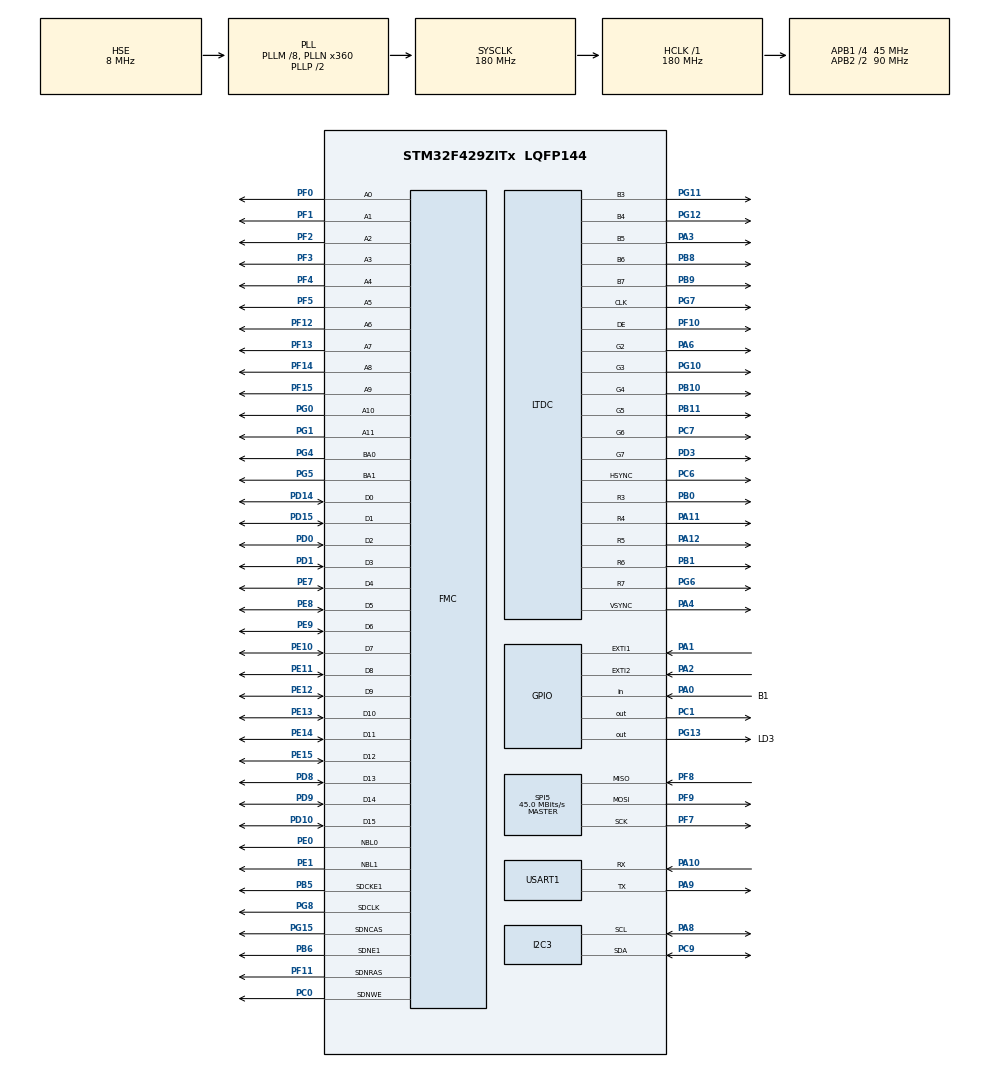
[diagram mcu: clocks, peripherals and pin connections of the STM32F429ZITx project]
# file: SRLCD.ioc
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DMA2D.ColorMode=DMA2D_OUTPUT_RGB565
LTDC.ActiveH=240
LTDC.ActiveW=320
Mcu.Family=STM32F4
Mcu.Name=STM32F429ZITx
Mcu.Package=LQFP144
NVIC.PriorityGroup=NVIC_PRIORITYGROUP_4
PA0/WKUP.GPIO_Label=B1
PA0/WKUP.Signal=GPIO_Input
PA1.Signal=GPXTI1
PA10.Mode=Asynchronous
PA10.Signal=USART1_RX
PA11.Mode=RGB565
PA11.Signal=LTDC_R4
PA12.Mode=RGB565
PA12.Signal=LTDC_R5
PA2.Signal=GPXTI2
PA3.Mode=RGB565
PA3.Signal=LTDC_B5
PA4.Mode=RGB565
PA4.Signal=LTDC_VSYNC
PA6.Mode=RGB565
PA6.Signal=LTDC_G2
PA8.Mode=I2C
PA8.Signal=I2C3_SCL
PA9.Mode=Asynchronous
PA9.Signal=USART1_TX
PB0.Mode=RGB565
PB0.Signal=LTDC_R3
PB1.Mode=RGB565
PB1.Signal=LTDC_R6
PB10.Mode=RGB565
PB10.Signal=LTDC_G4
PB11.Mode=RGB565
PB11.Signal=LTDC_G5
PB5.Mode=SdramChipSelect2_1
PB5.Signal=FMC_SDCKE1
PB6.Mode=SdramChipSelect2_1
PB6.Signal=FMC_SDNE1
PB8.Mode=RGB565
PB8.Signal=LTDC_B6
PB9.Mode=RGB565
PB9.Signal=LTDC_B7
PC0.Signal=FMC_SDNWE
PC1.Signal=GPIO_Output
PC6.Mode=RGB565
PC6.Signal=LTDC_HSYNC
PC7.Mode=RGB565
PC7.Signal=LTDC_G6
PC9.Mode=I2C
PC9.Signal=I2C3_SDA
PD0.Signal=FMC_D2_DA2
PD1.Signal=FMC_D3_DA3
PD10.Signal=FMC_D15_DA15
PD14.Signal=FMC_D0_DA0
PD15.Signal=FMC_D1_DA1
PD3.Mode=RGB565
PD3.Signal=LTDC_G7
PD8.Signal=FMC_D13_DA13
PD9.Signal=FMC_D14_DA14
PE0.Signal=FMC_NBL0
PE1.Signal=FMC_NBL1
PE10.Signal=FMC_D7_DA7
PE11.Signal=FMC_D8_DA8
PE12.Signal=FMC_D9_DA9
PE13.Signal=FMC_D10_DA10
PE14.Signal=FMC_D11_DA11
PE15.Signal=FMC_D12_DA12
PE7.Signal=FMC_D4_DA4
PE8.Signal=FMC_D5_DA5
PE9.Signal=FMC_D6_DA6
PF0.Signal=FMC_A0
PF1.Signal=FMC_A1
PF10.Mode=RGB565
PF10.Signal=LTDC_DE
PF11.Signal=FMC_SDNRAS
PF12.Signal=FMC_A6
PF13.Signal=FMC_A7
PF14.Signal=FMC_A8
PF15.Signal=FMC_A9
PF2.Signal=FMC_A2
PF3.Signal=FMC_A3
PF4.Signal=FMC_A4
PF5.Signal=FMC_A5
PF7.Mode=Full_Duplex_Master
PF7.Signal=SPI5_SCK
PF8.Mode=Full_Duplex_Master
PF8.Signal=SPI5_MISO
PF9.Mode=Full_Duplex_Master
PF9.Signal=SPI5_MOSI
PG0.Signal=FMC_A10
PG1.Signal=FMC_A11
PG10.Mode=RGB565
PG10.Signal=LTDC_G3
PG11.Mode=RGB565
PG11.Signal=LTDC_B3
PG12.Mode=RGB565
PG12.Signal=LTDC_B4
PG13.GPIO_Label=LD3
PG13.Signal=GPIO_Output
PG15.Signal=FMC_SDNCAS
PG4.Signal=FMC_A14_BA0
PG5.Signal=FMC_A15_BA1
PG6.Mode=RGB565
PG6.Signal=LTDC_R7
PG7.Mode=RGB565
PG7.Signal=LTDC_CLK
PG8.Signal=FMC_SDCLK
PH0/OSC_IN.Mode=HSE-External-Oscillator
PH0/OSC_IN.Signal=RCC_OSC_IN
PH1/OSC_OUT.Mode=HSE-External-Oscillator
PH1/OSC_OUT.Signal=RCC_OSC_OUT
ProjectManager.HeapSize=0x200
ProjectManager.StackSize=0x400
ProjectManager.TargetToolchain=STM32CubeIDE
RCC.48MHZClocksFreq_Value=120000000
RCC.AHBFreq_Value=180000000
RCC.APB1CLKDivider=RCC_HCLK_DIV4
RCC.APB1Freq_Value=45000000
RCC.APB1TimFreq_Value=90000000
RCC.APB2CLKDivider=RCC_HCLK_DIV2
RCC.APB2Freq_Value=90000000
RCC.APB2TimFreq_Value=180000000
RCC.CortexFreq_Value=180000000
RCC.HCLKFreq_Value=180000000
RCC.HSE_VALUE=8000000
RCC.HSI_VALUE=16000000
RCC.LSE_VALUE=32768
RCC.PLLM=8
RCC.PLLN=360
RCC.PLLQ=3
RCC.PLLSAIDivR=RCC_PLLSAIDIVR_4
RCC.PLLSAIN=100
RCC.PLLSAIR=5
RCC.PLLSourceVirtual=RCC_PLLSOURCE_HSE
RCC.SYSCLKFreq_VALUE=180000000
RCC.SYSCLKSource=RCC_SYSCLKSOURCE_PLLCLK
RCC.VCOOutputFreq_Value=360000000
SH.FMC_A0.0=FMC_A0,12b-sda1
SH.FMC_A1.0=FMC_A1,12b-sda1
SH.FMC_A10.0=FMC_A10,12b-sda1
SH.FMC_A11.0=FMC_A11,12b-sda1
SH.FMC_A14_BA0.0=FMC_BA0,FourSdramBanks1
SH.FMC_A15_BA1.0=FMC_BA1,FourSdramBanks1
SH.FMC_A2.0=FMC_A2,12b-sda1
SH.FMC_A3.0=FMC_A3,12b-sda1
SH.FMC_A4.0=FMC_A4,12b-sda1
SH.FMC_A5.0=FMC_A5,12b-sda1
SH.FMC_A6.0=FMC_A6,12b-sda1
SH.FMC_A7.0=FMC_A7,12b-sda1
SH.FMC_A8.0=FMC_A8,12b-sda1
SH.FMC_A9.0=FMC_A9,12b-sda1
SH.FMC_D0_DA0.0=FMC_D0,sd-16b-d1
SH.FMC_D10_DA10.0=FMC_D10,sd-16b-d1
SH.FMC_D11_DA11.0=FMC_D11,sd-16b-d1
SH.FMC_D12_DA12.0=FMC_D12,sd-16b-d1
SH.FMC_D13_DA13.0=FMC_D13,sd-16b-d1
SH.FMC_D14_DA14.0=FMC_D14,sd-16b-d1
SH.FMC_D15_DA15.0=FMC_D15,sd-16b-d1
SH.FMC_D1_DA1.0=FMC_D1,sd-16b-d1
SH.FMC_D2_DA2.0=FMC_D2,sd-16b-d1
SH.FMC_D3_DA3.0=FMC_D3,sd-16b-d1
SH.FMC_D4_DA4.0=FMC_D4,sd-16b-d1
SH.FMC_D5_DA5.0=FMC_D5,sd-16b-d1
SH.FMC_D6_DA6.0=FMC_D6,sd-16b-d1
SH.FMC_D7_DA7.0=FMC_D7,sd-16b-d1
SH.FMC_D8_DA8.0=FMC_D8,sd-16b-d1
SH.FMC_D9_DA9.0=FMC_D9,sd-16b-d1
SH.FMC_NBL0.0=FMC_NBL0,Sd2ByteEnable1
SH.FMC_NBL1.0=FMC_NBL1,Sd2ByteEnable1
SH.FMC_SDCLK.0=FMC_SDCLK,12b-sda1
SH.FMC_SDNCAS.0=FMC_SDNCAS,12b-sda1
SH.FMC_SDNRAS.0=FMC_SDNRAS,12b-sda1
SH.FMC_SDNWE.0=FMC_SDNWE,12b-sda1
SPI5.BaudRatePrescaler=SPI_BAUDRATEPRESCALER_2
SPI5.CalculateBaudRate=45.0 MBits/s
SPI5.Direction=SPI_DIRECTION_2LINES
SPI5.Mode=SPI_MODE_MASTER
SPI5.VirtualType=VM_MASTER
USART1.VirtualMode=VM_ASYNC
VP_DMA2D_VS_DMA2D.Mode=DMA2D_Activate
VP_TIM1_VS_ClockSourceINT.Mode=Internal
board=STM32F429I-DISC1

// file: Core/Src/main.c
/* USER CODE BEGIN Header */
/**
  ******************************************************************************
  * @file           : main.c
  * @brief          : Main program body
  ******************************************************************************
  * @attention
  *
  * Copyright (c) 2025 STMicroelectronics.
  * All rights reserved.
  *
  * This software is licensed under terms that can be found in the LICENSE file
  * in the root directory of this software component.
  * If no LICENSE file comes with this software, it is provided AS-IS.
  *
  ******************************************************************************
  */
/* USER CODE END Header */
#include "main.h"
#include "dma2d.h"
#include "i2c.h"
#include "ltdc.h"
#include "spi.h"
#include "tim.h"
#include "usart.h"
#include "gpio.h"
#include "fmc.h"

/* USER CODE BEGIN Includes */
#include "stm32f429i_discovery_lcd.h"
#include "stm32f4xx_hal.h"
#include "gyro.h"
#include "acc_ADXL345.h"
#include <string.h>
#include <math.h>
#include <maze.h>
#include <stdlib.h>
#include "stdio.h"
#include "ball.h"
/* USER CODE END Includes */

/* USER CODE BEGIN PD */
#define FRAMEBUFFER ((uint16_t *)0xD0000000)

#define SPEED 5.5f

#define gyro_x sensordata[0]
#define gyro_y sensordata[1]
#define gyro_z sensordata[2]
#define acc_x sensordata[3]
#define acc_y sensordata[4]
#define acc_z sensordata[5]
/* USER CODE END PD */

/* USER CODE BEGIN PV */
typedef enum {
    GAME_RUNNING,
    GAME_WIN,
    GAME_LOSE
} GameState;

/*0 nothing
  1 wall
  2 goal
  3 danger*/

/* USER CODE END PV */

void SystemClock_Config(void);
/* USER CODE BEGIN PFP */
void draw_cell(uint8_t tile_x, uint8_t tile_y, uint32_t color)
{
    BSP_LCD_SetTextColor(color);
    BSP_LCD_FillRect(
        MAZE_ORIGIN_X + tile_x * CELL_SIZE,
        MAZE_ORIGIN_Y + tile_y * CELL_SIZE,
        CELL_SIZE,
        CELL_SIZE
    );
}
void draw_ballSprite(float x_px, float y_px)
{
	int top_left_x = (int)(x_px - CELL_SIZE / 2);
	int top_left_y = (int)(y_px - CELL_SIZE / 2);

	for (int py = 0; py < CELL_SIZE; py++) {
		for (int px = 0; px < CELL_SIZE; px++) {
			if (ballSprite[py][px] == 1) {
				BSP_LCD_DrawPixel(top_left_x + px, top_left_y + py, LCD_COLOR_YELLOW);
	        }
	    }
	}
}

void draw_maze(const uint8_t maze_data[MAZE_HEIGHT][MAZE_WIDTH])
{
	for (int y = 0; y < MAZE_HEIGHT; y++) {
	        for (int x = 0; x < MAZE_WIDTH; x++) {
	        	uint32_t color;

	        	switch (maze_data[y][x]) {
	        	case 0:  color = LCD_COLOR_BLACK; break;
	        	case 1:  color = LCD_COLOR_DARKBLUE; break;
	        	case 2:  color = LCD_COLOR_GREEN; break;
	        	case 3:  color = LCD_COLOR_RED; break;
	        	default: color = LCD_COLOR_WHITE; break;
	        	}

	        	draw_cell(x, y, color);
	        }
	    }
}

void wait_for_user_button(void) {
    while (HAL_GPIO_ReadPin(GPIOA, GPIO_PIN_0) == GPIO_PIN_SET);
    HAL_Delay(200);
    while (HAL_GPIO_ReadPin(GPIOA, GPIO_PIN_0) == GPIO_PIN_RESET);
    HAL_Delay(200);
}

float* Gyro_CountBias(float sensordata[]);
int __io_putchar(int ch);
/* USER CODE END PFP */

int main(void)
{

  /* MCU Configuration--------------------------------------------------------*/

  /* Reset of all peripherals, Initializes the Flash interface and the Systick. */
  HAL_Init();

  /* Configure the system clock */
  SystemClock_Config();

  /* USER CODE BEGIN SysInit */
  Gyro_Init();
  ADXL345_Init();
  /* USER CODE END SysInit */

  /* Initialize all configured peripherals */
  MX_GPIO_Init();
  MX_DMA2D_Init();
  MX_FMC_Init();
  MX_I2C3_Init();
  MX_LTDC_Init();
  MX_SPI5_Init();
  MX_USART1_UART_Init();
  MX_TIM1_Init();
  /* USER CODE BEGIN 2 */
  BSP_LCD_Init();
  BSP_LCD_LayerDefaultInit(LCD_BACKGROUND_LAYER, LCD_FRAME_BUFFER);
  BSP_LCD_SelectLayer(LCD_BACKGROUND_LAYER);
  BSP_LCD_DisplayOn();
  BSP_LCD_Clear(LCD_COLOR_BLACK);

  update_ball_tile_position(&ball);

  float sensordata[6]; //0 gyro_x, 1 gyro_y, 2 gyro_z, 3 acc_x, 4 acc_y, 5 acc_z
  float roll=0, pitch=0;
  float acc_roll, acc_pitch, alpha = 0.985f;
  float dt = 0.01f; // 10ms loop
  float* gyro_bias; gyro_bias = Gyro_CountBias(sensordata);   // kompensacja odchyleń żyro

  uint8_t currTile = 0;
  uint8_t currLevel = 0;
  GameState currentGameState = GAME_RUNNING;
  uint32_t lastTick = HAL_GetTick();
  /* USER CODE END 2 */

  /* Infinite loop */
  while (1)
  {

    /* USER CODE BEGIN 3 */
	  HAL_GPIO_TogglePin(LD3_GPIO_Port, LD3_Pin);

	  uint32_t now = HAL_GetTick();
	  dt = (now - lastTick) / 1000.0f; // in seconds
	  lastTick = now;

	  /*
	   * ##########################
	   * #### GET ROLL & PITCH ####
	   * ##########################
	   * */
	  Gyro_ReadData(&gyro_x, &gyro_y, &gyro_z);
	  ADXL345_ReadAccel(&acc_x, &acc_y, &acc_z);
	  gyro_x -= gyro_bias[0];
	  gyro_y -= gyro_bias[1];
	  gyro_z -= gyro_bias[2];
	  acc_pitch = atan2f(-acc_x, sqrtf(acc_y*acc_y + acc_z*acc_z)) * 180.0f / M_PI;
	  acc_roll  = atan2f( acc_y, acc_z)							   * 180.0f / M_PI;

	  if(abs(gyro_y) > NOISE_THRESHOLD) roll  = alpha * (roll  + gyro_y * dt) + (1 - alpha) * acc_roll;
	  else roll = 0;
	  if(abs(gyro_x) > NOISE_THRESHOLD) pitch = alpha * (pitch + gyro_x * dt) + (1 - alpha) * acc_pitch;
	  else pitch = 0;

	  /*
	   * ############################
	   * ####  GAME STATE CHECK  ####
	   * ############################
	   * */

	  currTile = currMaze[ball.tile_y][ball.tile_x];

	  switch(currTile){
	  case 2:
		  currentGameState = GAME_WIN;
		  break;
	  case 3:
		  currentGameState = GAME_LOSE;
		  break;
	  default:
		  currentGameState = GAME_RUNNING;
	  }

	  /*
	   * ######################
	   * ##### GAME LOGIC #####
	   * ######################
	   * */
	  float vx, vy;
	  if(currentGameState == GAME_RUNNING){
		 draw_maze(currMaze);
		 vx = roll * SPEED;
		 vy = pitch * SPEED;

		 float new_x = ball.x_px + vx * dt;
		 int next_tile_x = (int)(new_x / CELL_SIZE);
		 if (currMaze[ball.tile_y][next_tile_x] != 1) {
		     ball.x_px = new_x;
		 }

		 float new_y = ball.y_px + vy * dt;
		 int next_tile_y = (int)(new_y / CELL_SIZE);
		 if (currMaze[next_tile_y][ball.tile_x] != 1) {
		     ball.y_px = new_y;
		 }

		 update_ball_tile_position(&ball);
		 draw_ballSprite(ball.x_px, ball.y_px);
	  }
	  else if(currentGameState == GAME_LOSE){
		  vx = 0; vy = 0;
		  BSP_LCD_Clear(LCD_COLOR_RED);
		  BSP_LCD_SetTextColor(LCD_COLOR_RED);
		  BSP_LCD_DisplayStringAt(0, LINE(5), (uint8_t *)"YOU LOSE!", CENTER_MODE);
		  BSP_LCD_DisplayStringAt(0, LINE(6), (uint8_t *)"Press button", CENTER_MODE);
		  BSP_LCD_DisplayStringAt(0, LINE(7), (uint8_t *)"to restart", CENTER_MODE);
		  wait_for_user_button();
		  reset_ball_position(&ball);
		  currentGameState = GAME_RUNNING;
	  }
	  else{
		  vx = 0; vy = 0;
		  BSP_LCD_Clear(LCD_COLOR_GREEN);
		  BSP_LCD_SetTextColor(LCD_COLOR_GREEN);
		  BSP_LCD_DisplayStringAt(0, LINE(5), (uint8_t *)"YOU WIN!", CENTER_MODE);
		  BSP_LCD_DisplayStringAt(0, LINE(6), (uint8_t *)"Press button", CENTER_MODE);
		  BSP_LCD_DisplayStringAt(0, LINE(7), (uint8_t *)"to advance", CENTER_MODE);
		  wait_for_user_button();

		  currLevel = (currLevel + 1) % 3;
		  switch (currLevel) {
		          case 0: currMaze = maze1;
		          	  	  BSP_LCD_Clear(LCD_COLOR_GREEN);
		          	  	  BSP_LCD_SetTextColor(LCD_COLOR_GREEN);
		          	  	  BSP_LCD_DisplayStringAt(0, LINE(5), (uint8_t *)"Level 1", CENTER_MODE);
		          	  	  HAL_Delay(1000);
		          	  	  break;
		          case 1: currMaze = maze2;
		          	  	  BSP_LCD_Clear(LCD_COLOR_GREEN);
		          	  	  BSP_LCD_SetTextColor(LCD_COLOR_GREEN);
		          	  	  BSP_LCD_DisplayStringAt(0, LINE(5), (uint8_t *)"Level 2", CENTER_MODE);
		          	  	  HAL_Delay(1000);
		          	  	  break;
		          case 2: currMaze = maze3;
		          	  	  BSP_LCD_Clear(LCD_COLOR_GREEN);
		          	  	  BSP_LCD_SetTextColor(LCD_COLOR_GREEN);
		          	  	  BSP_LCD_DisplayStringAt(0, LINE(5), (uint8_t *)"Level 3", CENTER_MODE);
		          	  	  HAL_Delay(1000);
		          	  	  break;
		  }

		  reset_ball_position(&ball);
		  currentGameState = GAME_RUNNING;
	  }

	  uint32_t frameTime = HAL_GetTick() - now;
	  (frameTime < 10) ? HAL_Delay(10 - frameTime) : HAL_Delay(10);
  }
  /* USER CODE END 3 */
}

void SystemClock_Config(void)
{
  RCC_OscInitTypeDef RCC_OscInitStruct = {0};
  RCC_ClkInitTypeDef RCC_ClkInitStruct = {0};

  /** Configure the main internal regulator output voltage
  */
  __HAL_RCC_PWR_CLK_ENABLE();
  __HAL_PWR_VOLTAGESCALING_CONFIG(PWR_REGULATOR_VOLTAGE_SCALE1);

  /** Initializes the RCC Oscillators according to the specified parameters
  * in the RCC_OscInitTypeDef structure.
  */
  RCC_OscInitStruct.OscillatorType = RCC_OSCILLATORTYPE_HSE;
  RCC_OscInitStruct.HSEState = RCC_HSE_ON;
  RCC_OscInitStruct.PLL.PLLState = RCC_PLL_ON;
  RCC_OscInitStruct.PLL.PLLSource = RCC_PLLSOURCE_HSE;
  RCC_OscInitStruct.PLL.PLLM = 8;
  RCC_OscInitStruct.PLL.PLLN = 360;
  RCC_OscInitStruct.PLL.PLLP = RCC_PLLP_DIV2;
  RCC_OscInitStruct.PLL.PLLQ = 3;
  if (HAL_RCC_OscConfig(&RCC_OscInitStruct) != HAL_OK)
  {
    Error_Handler();
  }

  /** Activate the Over-Drive mode
  */
  if (HAL_PWREx_EnableOverDrive() != HAL_OK)
  {
    Error_Handler();
  }

  /** Initializes the CPU, AHB and APB buses clocks
  */
  RCC_ClkInitStruct.ClockType = RCC_CLOCKTYPE_HCLK|RCC_CLOCKTYPE_SYSCLK
                              |RCC_CLOCKTYPE_PCLK1|RCC_CLOCKTYPE_PCLK2;
  RCC_ClkInitStruct.SYSCLKSource = RCC_SYSCLKSOURCE_PLLCLK;
  RCC_ClkInitStruct.AHBCLKDivider = RCC_SYSCLK_DIV1;
  RCC_ClkInitStruct.APB1CLKDivider = RCC_HCLK_DIV4;
  RCC_ClkInitStruct.APB2CLKDivider = RCC_HCLK_DIV2;

  if (HAL_RCC_ClockConfig(&RCC_ClkInitStruct, FLASH_LATENCY_5) != HAL_OK)
  {
    Error_Handler();
  }
}

/* USER CODE BEGIN 4 */
float* Gyro_CountBias(float sensordata[]){
	static float bias[3];
	for (int i = 0; i < 1000; ++i) {
		  Gyro_ReadData(&gyro_x, &gyro_y, &gyro_z);
	      bias[0] += gyro_x; bias[1] += gyro_y; bias[2] += gyro_z;
	      HAL_Delay(1);
	  }
	for(int j=0; j<3; j++)
	  bias[j] /= 1000.0f;

	return bias;
}
int __io_putchar(int ch) {
    HAL_UART_Transmit(&huart1, (uint8_t *)&ch, 1, HAL_MAX_DELAY);
    return ch;
}
/* USER CODE END 4 */

void Error_Handler(void)
{
  __disable_irq();
  while (1)
  {
  }
}
